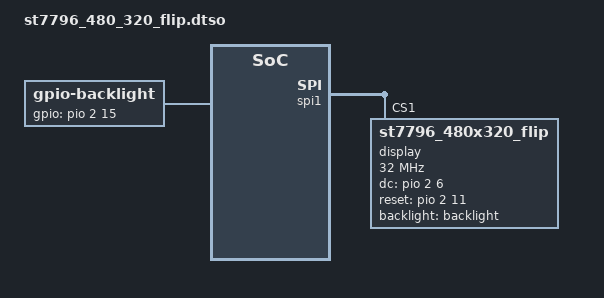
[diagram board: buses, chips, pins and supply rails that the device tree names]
/dts-v1/;
/plugin/;

/ {
    compatible = "xunlong,orangepi-zero3";

    fragment@0 {
        target-path = "/";
        __overlay__ {
            backlight: backlight {
                compatible = "gpio-backlight";
                gpios = <&pio 2 15 0>;
                default-on;
                default-brightness-level = <1>;
            };
        };
    };

    fragment@1 {
        target = <&spi1>;
        __overlay__ {
            status = "okay";
            #address-cells = <1>;
            #size-cells = <0>;

            pinctrl-names = "default";
            pinctrl-0 = <&spi1_pins &spi1_cs1_pin>;

            display@1 {
                compatible = "st7796_480x320_flip", "panel-mipi-dbi-spi";
                reg = <1>;
                spi-max-frequency = <32000000>;

                width-mm = <84>;
                height-mm = <56>;
                write-only;

                dc-gpios = <&pio 2 6 0>;
                reset-gpios = <&pio 2 11 0>;

                backlight = <&backlight>;

                panel-timing {
                    hactive = <480>;
                    vactive = <320>;
                    hback-porch = <0>;
                    vback-porch = <0>;
                    clock-frequency = <0>;
                    hfront-porch = <0>;
                    hsync-len = <0>;
                    vfront-porch = <0>;
                    vsync-len = <0>;
                };
            };
        };
    };
};
